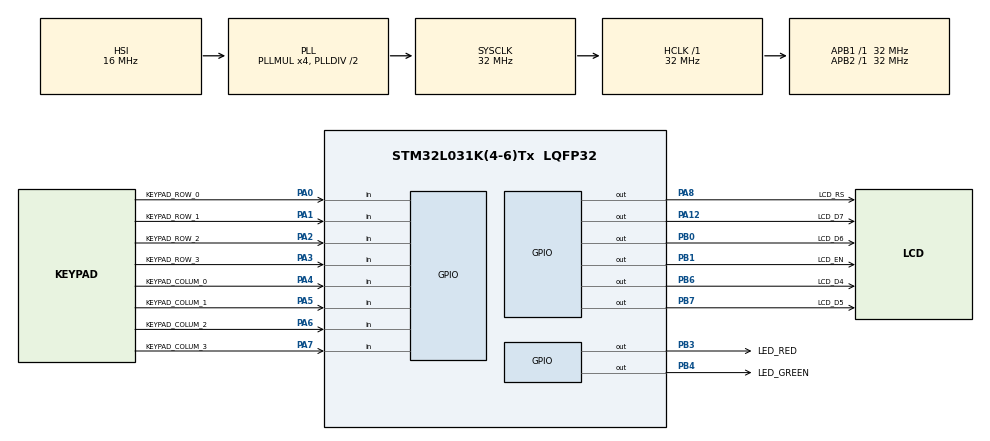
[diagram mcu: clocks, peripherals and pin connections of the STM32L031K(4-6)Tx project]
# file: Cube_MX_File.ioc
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Mcu.Family=STM32L0
Mcu.Name=STM32L031K(4-6)Tx
Mcu.Package=LQFP32
PA0-CK_IN.GPIO_Label=KEYPAD_ROW_0
PA0-CK_IN.GPIO_PuPd=GPIO_PULLUP
PA0-CK_IN.Signal=GPIO_Input
PA1.GPIO_Label=KEYPAD_ROW_1
PA1.GPIO_PuPd=GPIO_PULLUP
PA1.Signal=GPIO_Input
PA12.GPIO_Label=LCD_D7
PA12.Signal=GPIO_Output
PA13.GPIO_Label=TMS
PA13.Mode=Serial_Wire
PA13.Signal=SYS_SWDIO
PA14.GPIO_Label=TCK
PA14.Mode=Serial_Wire
PA14.Signal=SYS_SWCLK
PA2.GPIO_Label=KEYPAD_ROW_2
PA2.GPIO_PuPd=GPIO_PULLUP
PA2.Signal=GPIO_Input
PA3.GPIO_Label=KEYPAD_ROW_3
PA3.GPIO_PuPd=GPIO_PULLUP
PA3.Signal=GPIO_Input
PA4.GPIO_Label=KEYPAD_COLUM_0
PA4.GPIO_PuPd=GPIO_PULLUP
PA4.Signal=GPIO_Input
PA5.GPIO_Label=KEYPAD_COLUM_1
PA5.GPIO_PuPd=GPIO_PULLUP
PA5.Signal=GPIO_Input
PA6.GPIO_Label=KEYPAD_COLUM_2
PA6.GPIO_PuPd=GPIO_PULLUP
PA6.Signal=GPIO_Input
PA7.GPIO_Label=KEYPAD_COLUM_3
PA7.GPIO_PuPd=GPIO_PULLUP
PA7.Signal=GPIO_Input
PA8.GPIO_Label=LCD_RS
PA8.Signal=GPIO_Output
PB0.GPIO_Label=LCD_D6
PB0.Signal=GPIO_Output
PB1.GPIO_Label=LCD_EN
PB1.Signal=GPIO_Output
PB3.GPIO_Label=LED_RED
PB3.Signal=GPIO_Output
PB4.GPIO_Label=LED_GREEN
PB4.Signal=GPIO_Output
PB6.GPIO_Label=LCD_D4
PB6.Signal=GPIO_Output
PB7.GPIO_Label=LCD_D5
PB7.Signal=GPIO_Output
PC14-OSC32_IN.Mode=LSE-External-Oscillator
PC14-OSC32_IN.Signal=RCC_OSC32_IN
PC15-OSC32_OUT.Mode=LSE-External-Oscillator
PC15-OSC32_OUT.Signal=RCC_OSC32_OUT
ProjectManager.HeapSize=0x200
ProjectManager.StackSize=0x400
ProjectManager.TargetToolchain=EWARM V8.32
RCC.AHBFreq_Value=32000000
RCC.APB1Freq_Value=32000000
RCC.APB1TimFreq_Value=32000000
RCC.APB2Freq_Value=32000000
RCC.APB2TimFreq_Value=32000000
RCC.HCLKFreq_Value=32000000
RCC.HSE_VALUE=8000000
RCC.HSI16_VALUE=16000000
RCC.HSI48_VALUE=48000000
RCC.HSI_VALUE=16000000
RCC.MSI_VALUE=2097000
RCC.PLLMUL=RCC_PLLMUL_4
RCC.SYSCLKFreq_VALUE=32000000
RCC.SYSCLKSource=RCC_SYSCLKSOURCE_PLLCLK
RCC.VCOOutputFreq_Value=64000000
board=NUCLEO-L031K6

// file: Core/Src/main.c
/* USER CODE BEGIN Header */
/**
  ******************************************************************************
  * @file           : main.c
  * @brief          : Main program body
  ******************************************************************************
  * @attention
  *
  * Copyright (c) 2025 STMicroelectronics.
  * All rights reserved.
  *
  * This software is licensed under terms that can be found in the LICENSE file
  * in the root directory of this software component.
  * If no LICENSE file comes with this software, it is provided AS-IS.
  *
  ******************************************************************************
  */
/* USER CODE END Header */
#include "main.h"

/* USER CODE BEGIN Includes */
#include <stdbool.h>
/* USER CODE END Includes */

/* USER CODE BEGIN PD */
#define DEBOUNDE_DELAY 100
/* USER CODE END PD */

void SystemClock_Config(void);
static void MX_GPIO_Init(void);

int main(void)
{

  /* MCU Configuration--------------------------------------------------------*/

  /* Reset of all peripherals, Initializes the Flash interface and the Systick. */
  HAL_Init();

  /* USER CODE BEGIN Init */
  //Set up the systick timer to generate an interrupt every 1ms
  SysTick_Config(SystemCoreClock / 1000);
  /* USER CODE END Init */

  /* Configure the system clock */
  SystemClock_Config();

  /* Initialize all configured peripherals */
  MX_GPIO_Init();

  /* Infinite loop */
  while (1)
  {

  }
}

void SystemClock_Config(void)
{
  RCC_OscInitTypeDef RCC_OscInitStruct = {0};
  RCC_ClkInitTypeDef RCC_ClkInitStruct = {0};

  /** Configure the main internal regulator output voltage
  */
  __HAL_PWR_VOLTAGESCALING_CONFIG(PWR_REGULATOR_VOLTAGE_SCALE1);

  /** Initializes the RCC Oscillators according to the specified parameters
  * in the RCC_OscInitTypeDef structure.
  */
  RCC_OscInitStruct.OscillatorType = RCC_OSCILLATORTYPE_HSI;
  RCC_OscInitStruct.HSIState = RCC_HSI_ON;
  RCC_OscInitStruct.HSICalibrationValue = RCC_HSICALIBRATION_DEFAULT;
  RCC_OscInitStruct.PLL.PLLState = RCC_PLL_ON;
  RCC_OscInitStruct.PLL.PLLSource = RCC_PLLSOURCE_HSI;
  RCC_OscInitStruct.PLL.PLLMUL = RCC_PLLMUL_4;
  RCC_OscInitStruct.PLL.PLLDIV = RCC_PLLDIV_2;
  if (HAL_RCC_OscConfig(&RCC_OscInitStruct) != HAL_OK)
  {
    Error_Handler();
  }

  /** Initializes the CPU, AHB and APB buses clocks
  */
  RCC_ClkInitStruct.ClockType = RCC_CLOCKTYPE_HCLK|RCC_CLOCKTYPE_SYSCLK
                              |RCC_CLOCKTYPE_PCLK1|RCC_CLOCKTYPE_PCLK2;
  RCC_ClkInitStruct.SYSCLKSource = RCC_SYSCLKSOURCE_PLLCLK;
  RCC_ClkInitStruct.AHBCLKDivider = RCC_SYSCLK_DIV1;
  RCC_ClkInitStruct.APB1CLKDivider = RCC_HCLK_DIV1;
  RCC_ClkInitStruct.APB2CLKDivider = RCC_HCLK_DIV1;

  if (HAL_RCC_ClockConfig(&RCC_ClkInitStruct, FLASH_LATENCY_1) != HAL_OK)
  {
    Error_Handler();
  }
}

static void MX_GPIO_Init(void)
{
  GPIO_InitTypeDef GPIO_InitStruct = {0};

  /* GPIO Ports Clock Enable */
  __HAL_RCC_GPIOC_CLK_ENABLE();
  __HAL_RCC_GPIOA_CLK_ENABLE();
  __HAL_RCC_GPIOB_CLK_ENABLE();

  /*Configure GPIO pin Output Level */
  HAL_GPIO_WritePin(GPIOB, LCD_D6_Pin|LCD_EN_Pin|LED_RED_Pin|LED_GREEN_Pin
                          |LCD_D4_Pin|LCD_D5_Pin, GPIO_PIN_RESET);

  /*Configure GPIO pin Output Level */
  HAL_GPIO_WritePin(GPIOA, LCD_RS_Pin|LCD_D7_Pin, GPIO_PIN_RESET);

  /*Configure GPIO pins : KEYPAD_ROW_0_Pin KEYPAD_ROW_1_Pin KEYPAD_ROW_2_Pin KEYPAD_ROW_3_Pin
                           KEYPAD_COLUM_0_Pin KEYPAD_COLUM_1_Pin KEYPAD_COLUM_2_Pin KEYPAD_COLUM_3_Pin */
  GPIO_InitStruct.Pin = KEYPAD_ROW_0_Pin|KEYPAD_ROW_1_Pin|KEYPAD_ROW_2_Pin|KEYPAD_ROW_3_Pin
                          |KEYPAD_COLUM_0_Pin|KEYPAD_COLUM_1_Pin|KEYPAD_COLUM_2_Pin|KEYPAD_COLUM_3_Pin;
  GPIO_InitStruct.Mode = GPIO_MODE_INPUT;
  GPIO_InitStruct.Pull = GPIO_PULLUP;
  HAL_GPIO_Init(GPIOA, &GPIO_InitStruct);

  /*Configure GPIO pins : LCD_D6_Pin LCD_EN_Pin LED_RED_Pin LED_GREEN_Pin
                           LCD_D4_Pin LCD_D5_Pin */
  GPIO_InitStruct.Pin = LCD_D6_Pin|LCD_EN_Pin|LED_RED_Pin|LED_GREEN_Pin
                          |LCD_D4_Pin|LCD_D5_Pin;
  GPIO_InitStruct.Mode = GPIO_MODE_OUTPUT_PP;
  GPIO_InitStruct.Pull = GPIO_NOPULL;
  GPIO_InitStruct.Speed = GPIO_SPEED_FREQ_LOW;
  HAL_GPIO_Init(GPIOB, &GPIO_InitStruct);

  /*Configure GPIO pins : LCD_RS_Pin LCD_D7_Pin */
  GPIO_InitStruct.Pin = LCD_RS_Pin|LCD_D7_Pin;
  GPIO_InitStruct.Mode = GPIO_MODE_OUTPUT_PP;
  GPIO_InitStruct.Pull = GPIO_NOPULL;
  GPIO_InitStruct.Speed = GPIO_SPEED_FREQ_LOW;
  HAL_GPIO_Init(GPIOA, &GPIO_InitStruct);

}

void Error_Handler(void)
{
  __disable_irq();
  while (1)
  {
  }
}
